# SIM3L168_A register map
File version: 1
CPU: 
Registers are 32-bit, read-write, reset 0x0 unless marked. A register's access mark holds for its fields unless they carry their own. Offsets are from the block's base; [hi:lo] are bit positions; <NAME> marks a mode.

## CLKCTRL_0
Base 0x4002D000
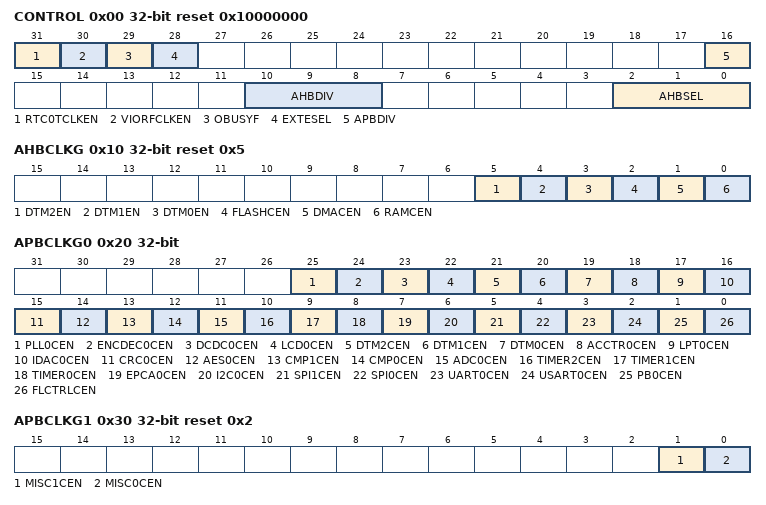
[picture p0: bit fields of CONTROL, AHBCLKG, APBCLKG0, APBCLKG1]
0x00 CONTROL reset 0x10000000 — Module Control
  [31] RTC0TCLKEN — RTC Timer Clock Enable.
    0=DISABLED (Disable the RTC0TCLK input.); 1=ENABLED (Enable the RTC0TCLK input.)
  [30] VIORFCLKEN — VIORF Clock Enable.
    0=DISABLED (Disable the VIORFCLK input.); 1=ENABLED (Enable the VIORFCLK input.)
  [29] OBUSYF ro — Oscillators Busy Flag.
    0=NOT_SET (AHB and APB oscillators are not busy.); 1=SET (AHB and APB oscillators are busy and the AHBSEL, AHBDIV, and APBDIV fields should not be modified.)
  [28] EXTESEL — External Clock Edge Select.
    0=BOTH_EDGES (External clock generated by both rising and falling edges of the external oscillator.); 1=RISING_ONLY (External clock generated by only rising edges of the external oscillator.)
  [16] APBDIV — APB Clock Divider.
    0=DIV1 (APB clock is the same as the AHB clock (divided by 1).); 1=DIV2 (APB clock is the AHB clock divided by 2.)
  [10:8] AHBDIV — AHB Clock Divider.
    0=DIV1 (AHB clock divided by 1.); 1=DIV2 (AHB clock divided by 2.); 2=DIV4 (AHB clock divided by 4.); 3=DIV8 (AHB clock divided by 8.); 4=DIV16 (AHB clock divided by 16.); 5=DIV32 (AHB clock divided by 32.); 6=DIV64 (AHB clock divided by 64.); 7=DIV128 (AHB clock divided by 128.)
  [2:0] AHBSEL — AHB Clock Source Select.
    0=LPOSC0 (AHB clock source is the Low-Power Oscillator.); 1=LFOSC0 (AHB clock source is the Low-Frequency Oscillator.); 2=RTC0TCLK (AHB clock source is the RTC0TCLK signal.); 3=EXTOSC0 (AHB clock source is the External Oscillator.); 4=VIORFCLK (AHB clock source is the VIORFCLK input pin.); 5=PLL0OSC (AHB clock source is the PLL.); 6=LPOSC0_DIV (AHB clock source is a divided version of the Low-Power Oscillator.)
0x10 AHBCLKG reset 0x5 — AHB Clock Gate
  [5] DTM2EN — DTM2 Clock Enable.
    0=DISABLED (Disable the AHB clock to Data Transfer Manager 2 (DTM2).); 1=ENABLED (Enable the AHB clock to Data Transfer Manager 2 (DTM2).)
  [4] DTM1EN — DTM1 Clock Enable.
    0=DISABLED (Disable the AHB clock to Data Transfer Manager 1 (DTM1).); 1=ENABLED (Enable the AHB clock to Data Transfer Manager 1 (DTM1).)
  [3] DTM0EN — DTM0 Clock Enable.
    0=DISABLED (Disable the AHB clock to Data Transfer Manager 0 (DTM0).); 1=ENABLED (Enable the AHB clock to Data Transfer Manager 0 (DTM0).)
  [2] FLASHCEN — Flash Clock Enable.
    0=DISABLED (Disable the AHB clock to the Flash.); 1=ENABLED (Enable the AHB clock to the Flash.)
  [1] DMACEN — DMA Clock Enable.
    0=DISABLED (Disable the AHB clock to the DMA Controller.); 1=ENABLED (Enable the AHB clock to the DMA Controller.)
  [0] RAMCEN — RAM Clock Enable.
    0=DISABLED (Disable the AHB clock to the RAM.); 1=ENABLED (Enable the AHB clock to the RAM.)
0x20 APBCLKG0 — APB Clock Gate 0
  [25] PLL0CEN — PLL0 Clock Enable.
    0=DISABLED (Disable the APB clock to the PLL0 registers.); 1=ENABLED (Enable the APB clock to the PLL0 registers.)
  [24] ENCDEC0CEN — ENCDEC0 Clock Enable.
    0=DISABLED (Disable the APB clock to the ENCDEC0 Module.); 1=ENABLED (Enable the APB clock to the ENCDEC0 Module.)
  [23] DCDC0CEN — DCDC0 Clock Enable.
    0=DISABLED (Disable the APB clock to the DCDC0 Module.); 1=ENABLED (Enable the APB clock to the DCDC0 Module.)
  [22] LCD0CEN — LCD0 Clock Enable.
    0=DISABLED (Disable the APB clock to the LCD0 Module.); 1=ENABLED (Enable the APB clock to the LCD0 Module.)
  [21] DTM2CEN — DTM2 Clock Enable.
    0=DISABLED (Disable the APB clock to the DTM2 Register interface.); 1=ENABLED (Enable the APB clock to the DTM2 Register interface.)
  [20] DTM1CEN — DTM1 Clock Enable.
    0=DISABLED (Disable the APB clock to the DTM1 Register interface.); 1=ENABLED (Enable the APB clock to the DTM1 Register interface.)
  [19] DTM0CEN — DTM0 Clock Enable.
    0=DISABLED (Disable the APB clock to the DTM0 Register interface.); 1=ENABLED (Enable the APB clock to the DTM0 Register interface.)
  [18] ACCTR0CEN — ACCTR0 Enable.
    0=DISABLED (Disable the APB clock to the ACCTR0 Module.); 1=ENABLED (Enable the APB clock to the ACCTR0 Module.)
  [17] LPT0CEN — LPT0 Clock Enable.
    0=DISABLED (Disable the APB clock to the LPTIMER0 Module.); 1=ENABLED (Enable the APB clock to the LPTIMER0 Module.)
  [16] IDAC0CEN — IDAC0 Clock Enable.
    0=DISABLED (Disable the APB clock to the IDAC0 Module.); 1=ENABLED (Enable the APB clock to the IDAC0 Module.)
  [15] CRC0CEN — CRC0 Clock Enable.
    0=DISABLED (Disable the APB clock to the CRC0 Module.); 1=ENABLED (Enable the APB clock to the CRC0 Module.)
  [14] AES0CEN — AES0 Clock Enable.
    0=DISABLED (Disable the APB clock to the AES0 Module.); 1=ENABLED (Enable the APB clock to the AES0 Module.)
  [13] CMP1CEN — CMP1 Clock Enable.
    0=DISABLED (Disable the APB clock to the Comparator 1 Module.); 1=ENABLED (Enable the APB clock to the Comparator 1 Module.)
  [12] CMP0CEN — CMP0 Clock Enable.
    0=DISABLED (Disable the APB clock to the Comparator 0 Module.); 1=ENABLED (Enable the APB clock to the Comparator 0 Module.)
  [11] ADC0CEN — SARADC0 Clock Enable.
    0=DISABLED (Disable the APB clock to the SARADC0 Module.); 1=ENABLED (Enable the APB clock to the SARADC0 Module.)
  [10] TIMER2CEN — TIMER2 Clock Enable.
    0=DISABLED (Disable the APB clock to the TIMER2 Module.); 1=ENABLED (Enable the APB clock to the TIMER2 Module.)
  [9] TIMER1CEN — TIMER1 Clock Enable.
    0=DISABLED (Disable the APB clock to the TIMER1 Module.); 1=ENABLED (Enable the APB clock to the TIMER1 Module.)
  [8] TIMER0CEN — TIMER0 Clock Enable.
    0=DISABLED (Disable the APB clock to the TIMER0 Module.); 1=ENABLED (Enable the APB clock to the TIMER0 Module.)
  [7] EPCA0CEN — EPCA0 Clock Enable.
    0=DISABLED (Disable the APB clock to the EPCA0 Module.); 1=ENABLED (Enable the APB clock to the EPCA0 Module.)
  [6] I2C0CEN — I2C0 Clock Enable.
    0=DISABLED (Disable the APB clock to the I2C0 Module.); 1=ENABLED (Enable the APB clock to the I2C0 Module.)
  [5] SPI1CEN — SPI1 Clock Enable.
    0=DISABLED (Disable the APB clock to the SPI1 Module.); 1=ENABLED (Enable the APB clock to the SPI1 Module.)
  [4] SPI0CEN — SPI0 Clock Enable.
    0=DISABLED (Disable the APB clock to the SPI0 Module.); 1=ENABLED (Enable the APB clock to the SPI0 Module.)
  [3] UART0CEN — UART0 Clock Enable.
    0=DISABLED (Disable the APB clock to the UART0 Module.); 1=ENABLED (Enable the APB clock to the UART0 Module.)
  [2] USART0CEN — USART0 Clock Enable.
    0=DISABLED (Disable the APB clock to the USART0 Module.); 1=ENABLED (Enable the APB clock to the USART0 Module.)
  [1] PB0CEN — Port Bank Clock Enable.
    0=DISABLED (Disable the APB clock to the Port Bank Modules.); 1=ENABLED (Enable the APB clock to the Port Bank Modules.)
  [0] FLCTRLCEN — Flash Controller Clock Enable.
    0=DISABLED (Disable the APB clock to the Flash Controller Module (FLASHCTRL0).); 1=ENABLED (Enable the APB clock to the Flash Controller Module (FLASHCTRL0).)
0x30 APBCLKG1 reset 0x2 — APB Clock Gate 1
  [1] MISC1CEN — Miscellaneous 1 Clock Enable.
    0=DISABLED (Disable the APB clock to the Watchdog Timer (WDTIMER0) and DMA Crossbar (DMAXBAR0) modules.); 1=ENABLED (Enable the APB clock to the Watchdog Timer (WDTIMER0) and DMA Crossbar (DMAXBAR0) modules.)
  [0] MISC0CEN — Miscellaneous 0 Clock Enable.
    0=DISABLED (Disable the APB clock to the VMON0, LDO0, EXTOSC0, LPOSC0, RTC0 and RSTSRC modules.); 1=ENABLED (Enable the APB clock to the VMON0, LDO0, EXTOSC0, LPOSC0, RTC0 and RSTSRC modules.)
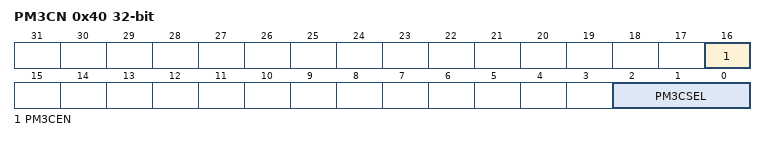
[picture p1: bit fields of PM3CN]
0x40 PM3CN — Power Mode 3 Clock Control
  [16] PM3CEN — Power Mode 3 Fast-Wake Clock Enable.
    0=DISABLED (Disable the core clock when in Power Mode 3.); 1=ENABLED (The core clock is enabled and runs off the clock selected by PM3CSEL in Power Mode 3.)
  [2:0] PM3CSEL — Power Mode 3 Fast-Wake Clock Source.
    0=LPOSC0_DIV (Power Mode 3 clock source is the Low-Power Oscillator.); 1=LFOSC0 (Power Mode 3 clock source is the Low-Frequency Oscillator.); 2=RTC0TCLK (Power Mode 3 clock source is the RTC0TCLK signal.); 3=EXTOSC0 (Power Mode 3 clock source is the External Oscillator.); 4=VIORFCLK (Power Mode 3 clock source is the VIORFCLK input pin.); 5=PLL0OSC (Power Mode 3 clock source is the PLL.); 6=LPOSC0 (Power Mode 3 clock source is a divided version of the Low-Power Oscillator.)
0x60 CONFIG — Configuration Options
  [0] PMSEL — Power Mode Select.
    0=PM8_DIS (Power Mode < PM8.); 1=PM8_EN (Power Mode = PM8.)
